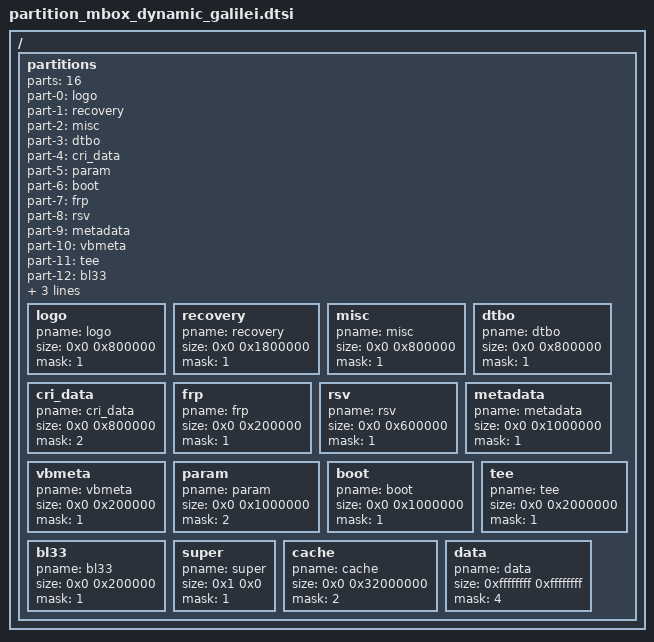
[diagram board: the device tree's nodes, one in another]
/*
 * Amlogic partition set for Beelink GT-King Pro (galilei), dynamic partitions.
 *
 * Same layout as partition_mbox_dynamic_deadpool.dtsi (ADT-3 / radxa02pro)
 * but with a 2 MiB "bl33" partition (chainloaded u-boot) and a 4 GiB "super" partition: the eMMC is 61 GB and an Android TV
 * build with GApps does not fit the 1.9 GiB deadpool super.
 * BOARD_SUPER_PARTITION_SIZE in device/beelink/galilei/BoardConfig.mk
 * must match the super size below (0x100000000 = 4294967296).
 *
 * Copyright (c) 2017-2017 Amlogic Ltd
 *
 * This file is licensed under a dual GPLv2 or BSD license.
 *
 */

#include "firmware_avb_deadpool.dtsi"

/ {
    partitions: partitions{
		parts = <16>;
		part-0 = <&logo>;
		part-1 = <&recovery>;
		part-2 = <&misc>;
		part-3 = <&dtbo>;
		part-4 = <&cri_data>;
		part-5 = <&param>;
		part-6 = <&boot>;
		part-7 = <&frp>;
		part-8 = <&rsv>;
		part-9 = <&metadata>;
		part-10 = <&vbmeta>;
		part-11 = <&tee>;
		part-12 = <&bl33>;
		part-13 = <&super>;
		part-14 = <&cache>;
		part-15 = <&data>;

		logo:logo{
			pname = "logo";
			size = <0x0 0x800000>;
			mask = <1>;
		};
		recovery:recovery{
			pname = "recovery";
			size = <0x0 0x1800000>;
			mask = <1>;
		};
		misc:misc{
			pname = "misc";
			size = <0x0 0x800000>;
			mask = <1>;
		};
		dtbo:dtbo{
			pname = "dtbo";
			size = <0x0 0x800000>;
			mask = <1>;
		};
		cri_data:cri_data
		{
			pname = "cri_data";
			size = <0x0 0x800000>;
			mask = <2>;
		};
		frp:frp{
			pname = "frp";
			size = <0x0 0x200000>;
			mask = <1>;
		};
		rsv:rsv{
			pname = "rsv";
			size = <0x0 0x600000>;
			mask = <1>;
		};
		metadata:metadata{
			pname = "metadata";
			size = <0x0 0x1000000>;
			mask = <1>;
		};
		vbmeta:vbmeta{
			pname = "vbmeta";
			size = <0x0 0x200000>;
			mask = <1>;
		};
		param:param{
			pname = "param";
			size = <0x0 0x1000000>;
			mask = <2>;
		};
		boot:boot
		{
			pname = "boot";
			size = <0x0 0x1000000>;
			mask = <1>;
		};
		tee:tee{
			pname = "tee";
			size = <0x0 0x2000000>;
			mask = <1>;
		};
		/* raw galilei u-boot BL33 (build/u-boot.bin, ~1.2 MiB): the stock bootloader's env
		 * 'preboot' chainloads it (store read + go) so BL2/BL30/BL31/BL33 of Beelink stay untouched */
		bl33:bl33{
			pname = "bl33";
			size = <0x0 0x200000>;
			mask = <1>;
		};
		super:super
		{
			pname = "super";
			size = <0x1 0x0>;
			mask = <1>;
		};
		cache:cache
		{
			pname = "cache";
			size = <0x0 0x32000000>;
			mask = <2>;
		};
		data:data
		{
			pname = "data";
			size = <0xffffffff 0xffffffff>;
			mask = <4>;
		};
	};
};/* end of / */
